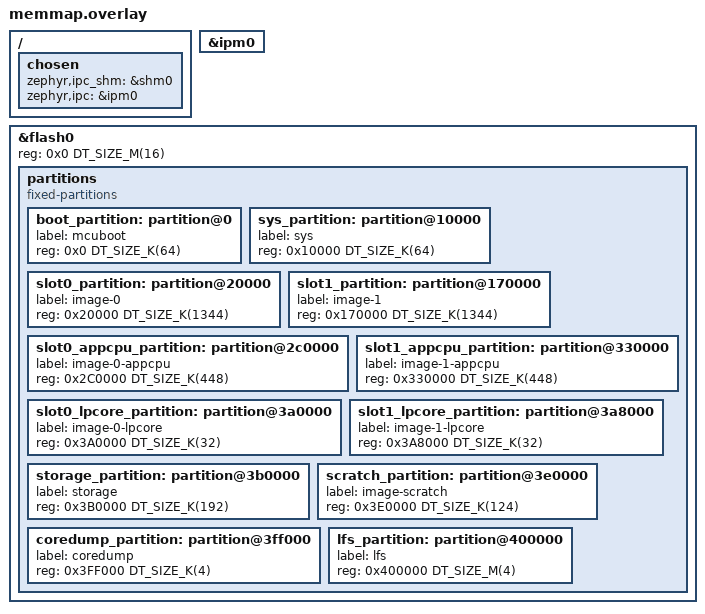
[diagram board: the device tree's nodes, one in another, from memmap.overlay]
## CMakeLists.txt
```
# cmake boilerplate
cmake_minimum_required(VERSION 3.5.0)

set(PROJECT_ROOT_DIR ${CMAKE_CURRENT_LIST_DIR}/../../)

# add modules
list(APPEND EXTRA_ZEPHYR_MODULES
    ${PROJECT_ROOT_DIR}/modules/reiki_sdk_zephyr
)

# import overlays for CPUs
# set(DTC_OVERLAY_FILE ${PROJECT_ROOT_DIR}/overlays/waveshare_1_47_tft_esp32s3.overlay)
set(DTC_OVERLAY_FILE ${CMAKE_CURRENT_LIST_DIR}/memmap.overlay)

# add extra configuration
set(EXTRA_CONF_FILE ${CMAKE_CURRENT_LIST_DIR}/prj.conf)

# add zephyr package
find_package(Zephyr REQUIRED HINTS $ENV{ZEPHYR_BASE})

# declare project
project(BLEGifyZephyr)

# add sources
file(GLOB_RECURSE srcs ${CMAKE_CURRENT_LIST_DIR}/src/*.c*)

target_sources(app
    PRIVATE ${srcs}
)

target_include_directories(app
    PUBLIC ${CMAKE_CURRENT_LIST_DIR}/include/
)
```

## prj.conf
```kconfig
CONFIG_SHELL=y
CONFIG_SERIAL=y
CONFIG_UART_CONSOLE=y
CONFIG_SHELL_PROMPT_UART="¯\\_(ツ)_/¯ =:"

CONFIG_PRINTK=y
CONFIG_STDOUT_CONSOLE=y
CONFIG_LOG=y

CONFIG_ESPTOOLPY_FLASHSIZE_8MB=y
CONFIG_FLASH=y
CONFIG_FLASH_MAP=y
CONFIG_SOC_FLASH_ESP32=y

CONFIG_FILE_SYSTEM=y
CONFIG_FILE_SYSTEM_LITTLEFS=y
CONFIG_FILE_SYSTEM_SHELL=y

CONFIG_DISK_ACCESS=y
CONFIG_FILE_SYSTEM=y
CONFIG_FILE_SYSTEM_SHELL=y
CONFIG_FAT_FILESYSTEM_ELM=y
CONFIG_FS_FATFS_MOUNT_MKFS=y
CONFIG_FILE_SYSTEM_MKFS=y
CONFIG_TEST_RANDOM_GENERATOR=y
CONFIG_FILE_SYSTEM_EXT2=y

CONFIG_FS_LOG_LEVEL_DBG=n

CONFIG_BT=y
CONFIG_BT_DEVICE_NAME="Gify"
CONFIG_BT_PERIPHERAL=y
CONFIG_BT_GATT_CLIENT=y
CONFIG_BT_SHELL=y
CONFIG_BT_RX_STACK_SIZE=4096

CONFIG_BT_OTS=y
CONFIG_BT_OTS_SECONDARY_SVC=y
CONFIG_BT_OTS_DIR_LIST_OBJ=y
CONFIG_BT_OTS_OBJ_NAME_WRITE_SUPPORT=y
CONFIG_BT_OTS_OACP_WRITE_SUPPORT=y
CONFIG_BT_OTS_OACP_PATCH_SUPPORT=y
CONFIG_BT_OTS_OACP_CREATE_SUPPORT=y
CONFIG_BT_OTS_OACP_DELETE_SUPPORT=y
CONFIG_BT_OTS_OACP_CHECKSUM_SUPPORT=y
CONFIG_BT_AUTO_PHY_PERIPHERAL_2M=y
CONFIG_BT_GATT_AUTO_UPDATE_MTU=y
CONFIG_BT_MAX_CONN=1

# Give the main/init thread more headroom; FATFS mkfs/mount and logging were
# running on this stack before main(), and a small default stack can corrupt
# scheduler state and crash later during disconnect.
CONFIG_ASSERT=y
CONFIG_MAIN_STACK_SIZE=4096
CONFIG_STACK_SENTINEL=y
CONFIG_INIT_STACKS=y
CONFIG_THREAD_STACK_INFO=y

# sysworkq blows up after disconnect; give it more headroom
CONFIG_SYSTEM_WORKQUEUE_STACK_SIZE=4096

# HCI ACL buffers size
# BT_L2CAP_RX_MTU = CONFIG_BT_BUF_ACL_RX_SIZE - BT_L2CAP_HDR_SIZE
CONFIG_BT_BUF_ACL_RX_SIZE=2000

# L2CAP SDU/PDU TX MTU
CONFIG_BT_L2CAP_TX_MTU=2000

CONFIG_OPENAMP=y
CONFIG_OPENAMP_SLAVE=n
CONFIG_FS_FATFS_CUSTOM_MOUNT_POINT_COUNT=2
```

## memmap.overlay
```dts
/*
* Copyright (c) 2024-2025 Espressif Systems (Shanghai) Co., Ltd.
*
* SPDX-License-Identifier: Apache-2.0
*/

/ {
    chosen {
        zephyr,ipc_shm = &shm0;
        zephyr,ipc = &ipm0;
    };
};

&ipm0 {
    status = "okay";
};

&flash0 {
    reg = <0x0 DT_SIZE_M(16)>;
    status = "okay";
    
    partitions {
        compatible = "fixed-partitions";
        #address-cells = <1>;
        #size-cells = <1>;
        
        boot_partition: partition@0 {
            label = "mcuboot";
            reg = <0x0 DT_SIZE_K(64)>;
        };
        
        sys_partition: partition@10000 {
            label = "sys";
            reg = <0x10000 DT_SIZE_K(64)>;
        };
        
        slot0_partition: partition@20000 {
            label = "image-0";
            reg = <0x20000 DT_SIZE_K(1344)>;
        };
        
        slot1_partition: partition@170000 {
            label = "image-1";
            reg = <0x170000 DT_SIZE_K(1344)>;
        };
        
        slot0_appcpu_partition: partition@2c0000 {
            label = "image-0-appcpu";
            reg = <0x2C0000 DT_SIZE_K(448)>;
        };
        
        slot1_appcpu_partition: partition@330000 {
            label = "image-1-appcpu";
            reg = <0x330000 DT_SIZE_K(448)>;
        };
        
        slot0_lpcore_partition: partition@3a0000 {
            label = "image-0-lpcore";
            reg = <0x3A0000 DT_SIZE_K(32)>;
        };
        
        slot1_lpcore_partition: partition@3a8000 {
            label = "image-1-lpcore";
            reg = <0x3A8000 DT_SIZE_K(32)>;
        };
        
        storage_partition: partition@3b0000 {
            label = "storage";
            reg = <0x3B0000 DT_SIZE_K(192)>;
        };
        
        scratch_partition: partition@3e0000 {
            label = "image-scratch";
            reg = <0x3E0000 DT_SIZE_K(124)>;
        };
        
        coredump_partition: partition@3ff000 {
            label = "coredump";
            reg = <0x3FF000 DT_SIZE_K(4)>;
        };
        
        lfs_partition: partition@400000 {
            label = "lfs";
            reg = <0x400000 DT_SIZE_M(4)>;
        };
    };
};

/* Remaining flash size is 0kB
* Last used address is 0x3FFFFF
*/
```

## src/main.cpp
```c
#include <zephyr/kernel.h>
#include <zephyr/device.h>
#include <zephyr/drivers/gpio.h>

#include <zephyr/logging/log.h>
LOG_MODULE_REGISTER(main);

void boot_banner()
{
    printk(R"(
         _____________________________   
        /        _____________        \
        | == .  |             |     o |
        |   _   |             |   B   |
        |  / \  |             | A  O  |
        | | O | |             |  O    |
        |  \_/  |             |       |
        | B L E |             | . . . |
        |  :::  |             | . . . |
        |  :::  |_____________| . . . |
        |           G I F Y           |
        \_____________________________/
    )"
           "\n");
}

int main()
{
    boot_banner();

    while (1) {
        k_sleep(K_MSEC(1000));
    }

    return 0;
}
```

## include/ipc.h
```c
/*
 * Copyright (c) 2018 Nordic Semiconductor ASA
 * Copyright (c) 2018-2019 Linaro Limited
 *
 * SPDX-License-Identifier: Apache-2.0
 */

#pragma once

#define VDEV_START_ADDR  DT_REG_ADDR(DT_CHOSEN(zephyr_ipc_shm))
#define VDEV_SIZE        DT_REG_SIZE(DT_CHOSEN(zephyr_ipc_shm))

#define VDEV_STATUS_ADDR VDEV_START_ADDR
#define VDEV_STATUS_SIZE 0x400

#define SHM_START_ADDR   (VDEV_START_ADDR + VDEV_STATUS_SIZE)
#define SHM_SIZE         (VDEV_SIZE - VDEV_STATUS_SIZE)
#define SHM_DEVICE_NAME  "sramx.shm"

#define VRING_COUNT      2
#define VRING_RX_ADDRESS (VDEV_START_ADDR + SHM_SIZE - VDEV_STATUS_SIZE)
#define VRING_TX_ADDRESS (VDEV_START_ADDR + SHM_SIZE)
#define VRING_ALIGNMENT  4
#define VRING_SIZE       16
```

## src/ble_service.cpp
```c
#include <stddef.h>
#include <errno.h>

#include <zephyr/types.h>
#include <zephyr/kernel.h>
#include <zephyr/sys/printk.h>

#include <zephyr/bluetooth/bluetooth.h>
#include <zephyr/bluetooth/hci.h>
#include <zephyr/bluetooth/conn.h>
#include <zephyr/bluetooth/uuid.h>
#include <zephyr/bluetooth/gatt.h>
#include <zephyr/sys/byteorder.h>
#include <zephyr/init.h>
#include <zephyr/logging/log.h>
LOG_MODULE_REGISTER(BLE_Service);

static const struct bt_data ad[] = {
    BT_DATA_BYTES(BT_DATA_FLAGS, (BT_LE_AD_GENERAL | BT_LE_AD_NO_BREDR)),
};

static const struct bt_data sd[] = {
    BT_DATA(BT_DATA_NAME_COMPLETE, CONFIG_BT_DEVICE_NAME, sizeof(CONFIG_BT_DEVICE_NAME) - 1),
};

static void mtu_updated(struct bt_conn* conn, uint16_t tx, uint16_t rx)
{
    printk("Updated MTU: TX: %d RX: %d bytes\n", tx, rx);
}
static struct bt_gatt_cb gatt_callbacks = { .att_mtu_updated = mtu_updated };

int ble_service_init()
{
    int rc = bt_enable(NULL);
    if (rc) {
        LOG_ERR("Bluetooth init failed (err %d)", rc);
        return rc;
    }
    LOG_INF("Bluetooth initialized");

    bt_gatt_cb_register(&gatt_callbacks);

    rc = bt_le_adv_start(BT_LE_ADV_CONN_FAST_1, ad, ARRAY_SIZE(ad), sd, ARRAY_SIZE(sd));
    if (rc) {
        LOG_ERR("Advertising failed to start (err %d)", rc);
        return rc;
    }

    LOG_INF("Advertising successfully started");
    return 0;
}

SYS_INIT(ble_service_init, APPLICATION, CONFIG_APPLICATION_INIT_PRIORITY);
```

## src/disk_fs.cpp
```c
#include <zephyr/kernel.h>
#include <zephyr/init.h>
#include <zephyr/display/cfb.h>
#include <zephyr/drivers/gpio.h>
#include <zephyr/drivers/pwm.h>
#include <zephyr/random/random.h>
#include <zephyr/input/input.h>
#include <zephyr/logging/log.h>
#include <zephyr/fs/fs.h>
#include <zephyr/storage/disk_access.h>
#include <ff.h>

LOG_MODULE_REGISTER(diskfs);

#define DISK_DRIVE_NAME "SD"
#define DISK_MOUNT_PT   "/SD:"

static FATFS             fat_fs;
static struct fs_mount_t mp = {
    .type      = FS_FATFS,
    .mnt_point = DISK_MOUNT_PT,
    .fs_data   = &fat_fs,
    .flags     = FS_MOUNT_FLAG_NO_FORMAT,
};

static const char* disk_mount_pt = DISK_MOUNT_PT;

int diskfs_svc_init()
{
    // FATFS mkfs parameters: auto-select FAT type and cluster size.
    MKFS_PARM mkfs_cfg{};
    mkfs_cfg.fmt     = FM_ANY | FM_SFD; // Format as super-floppy (no partition table)
    mkfs_cfg.n_fat   = 1;               // Single FAT table
    mkfs_cfg.align   = 0;               // Query sector size from diskio
    mkfs_cfg.n_root  = CONFIG_FS_FATFS_MAX_ROOT_ENTRIES;
    mkfs_cfg.au_size = 0; // Auto calculate cluster size

    mp.mnt_point = disk_mount_pt;

    /* Format the drive (mkfs) using FATFS across full device and then mount it */
    const char* fat_dev = DISK_DRIVE_NAME ":"; // e.g. "SD:"
    int         ret     = fs_mkfs(FS_FATFS, (uintptr_t)fat_dev, &mkfs_cfg, 0);
    if (ret != 0) {
        LOG_ERR("mkfs FATFS failed: %d", ret);
    }

    int res = fs_mount(&mp);
    if (res == 0u) {
        LOG_INF("FATFS disk mounted.");
    } else {
        LOG_ERR("Error mounting FATFS disk: %d", res);
    }

    /* Optional: print basic FS stats to verify mount */
    if (res == 0) {
        struct fs_statvfs stat;

        int sret = fs_statvfs(mp.mnt_point, &stat);
        if (sret == 0) {
            LOG_INF("FATFS stats: bsize=%lu blocks=%lu free=%lu", (unsigned long)stat.f_bsize,
                    (unsigned long)stat.f_blocks, (unsigned long)stat.f_bfree);
        } else {
            LOG_ERR("fs_statvfs failed: %d", sret);
        }
    }

    return 0;
}

SYS_INIT(diskfs_svc_init, APPLICATION, CONFIG_APPLICATION_INIT_PRIORITY);
```

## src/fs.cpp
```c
#include <cstddef>
#include <cstdint>

#include <zephyr/kernel.h>
#include <zephyr/device.h>
#include <zephyr/fs/fs.h>
#include <zephyr/drivers/gpio.h>

#include <zephyr/storage/flash_map.h>
#include <zephyr/fs/littlefs.h>
#include <zephyr/drivers/flash.h>

#include <zephyr/logging/log.h>
LOG_MODULE_REGISTER(LittleFS);

FS_LITTLEFS_DECLARE_DEFAULT_CONFIG(storage);
static struct fs_mount_t lfs_storage_mnt = {
    .type        = FS_LITTLEFS,
    .mnt_point   = "/flash",
    .fs_data     = &storage,
    .storage_dev = (void*)FIXED_PARTITION_ID(lfs_partition),
};

static int littlefs_flash_erase(unsigned int id)
{
    const struct flash_area* pfa;
    int                      rc = flash_area_open(id, &pfa);
    if (rc < 0) {
        LOG_ERR("FAIL: unable to find flash area %u: %d\n", id, rc);
        return rc;
    }

    LOG_PRINTK("Area %u at 0x%x on %s for %u bytes\n", id, (unsigned int)pfa->fa_off,
               pfa->fa_dev->name, (unsigned int)pfa->fa_size);

    /* Optional wipe flash contents */
    rc = flash_area_flatten(pfa, 0, pfa->fa_size);
    LOG_ERR("Erasing flash area ... %d", rc);

    flash_area_close(pfa);
    return rc;
}

int init_file_system()
{
    struct fs_mount_t*       mp  = &lfs_storage_mnt;
    const struct flash_area* pfa = nullptr;

    int rc = flash_area_open((uintptr_t)mp->storage_dev, &pfa);
    if (rc < 0) {
        LOG_ERR("FAIL: unable to find flash area %u: %d\n", mp->storage_dev, rc);
        return rc;
    }
    LOG_INF("Flash Area Size is %lu kb", pfa->fa_size / 1024u);

    // rc = littlefs_flash_erase((uintptr_t)mp->storage_dev);
    // if (rc < 0) {
    //     return rc;
    // }

    rc = fs_mount(mp);
    if (rc < 0) {
        LOG_ERR("FAIL: mount id %" PRIuPTR " at %s: %d\n", (uintptr_t)mp->storage_dev,
                mp->mnt_point, rc);
        return rc;
    }

    LOG_INF("LittleFS initialized on Flash.");
    return 0;
}

SYS_INIT(init_file_system, APPLICATION, CONFIG_APPLICATION_INIT_PRIORITY);

/* shell command for erasing flash */

#include <zephyr/shell/shell.h>

static int cmd_erase_flash(const struct shell* shell, size_t argc, char** argv)
{
    ARG_UNUSED(argc);
    ARG_UNUSED(argv);

    /* re mount */
    int rc = fs_unmount(&lfs_storage_mnt);
    if (rc < 0) {
        shell_print(shell, "Error unmounting LittleFS before erase: %d", rc);
        return rc;
    }

    rc = littlefs_flash_erase(FIXED_PARTITION_ID(lfs_partition));
    if (rc < 0) {
        shell_print(shell, "Error erasing flash: %d", rc);
        return rc;
    }

    rc = fs_mount(&lfs_storage_mnt);
    if (rc < 0) {
        shell_print(shell, "Error mounting LittleFS after erase: %d", rc);
        return rc;
    }

    shell_print(shell, "Flash erase completed.");
    return 0;
}

/* flash submenu containing erase command */
SHELL_STATIC_SUBCMD_SET_CREATE(sub_flash,
                               SHELL_CMD(erase, NULL, "Erase LittleFS flash partition",
                                         cmd_erase_flash),
                               SHELL_SUBCMD_SET_END);
SHELL_CMD_REGISTER(flash, &sub_flash, "Flash operations", NULL);
```

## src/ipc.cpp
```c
#include <stdio.h>
#include <stdlib.h>
#include <string.h>
#include <errno.h>

#include <zephyr/kernel.h>
#include <zephyr/drivers/ipm.h>
#include <zephyr/init.h>

#include <openamp/open_amp.h>

#include <ipc.h>

static const struct device *const ipm_handle =
	DEVICE_DT_GET(DT_CHOSEN(zephyr_ipc));

int32_t init_ipc()
{
	if (!device_is_ready(ipm_handle)) {
		printk("IPM device is not ready\n");
		return -ENODEV;
	}

    struct metal_init_params metal_params = METAL_INIT_DEFAULTS;
    int status = metal_init(&metal_params);
    if (status != 0) {
        printk("metal_init: failed - error code %d\n", status);
        return status;
    }



    return 0;
}
```
